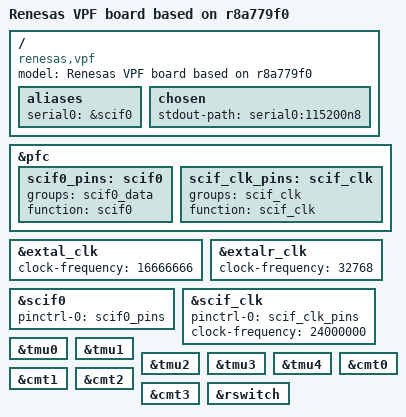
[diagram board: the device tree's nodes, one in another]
// SPDX-License-Identifier: GPL-2.0
/*
 * Device Tree Source for the s4 vpf board
 *
 * Copyright (C) 2020 Renesas Electronics Corp.
 */

/dts-v1/;
#include "r8a779f0.dtsi"

/ {
	model = "Renesas VPF board based on r8a779f0";
	compatible = "renesas,vpf", "renesas,r8a779f0";

	aliases {
		serial0 = &scif0;
	};

	chosen {
		stdout-path = "serial0:115200n8";
	};
};

&pfc {
	scif0_pins: scif0 {
		groups = "scif0_data";
		function = "scif0";
	};

	scif_clk_pins: scif_clk {
		groups = "scif_clk";
		function = "scif_clk";
	};
};

&extal_clk {
	clock-frequency = <16666666>;
};

&extalr_clk {
	clock-frequency = <32768>;
};

&scif0 {
	pinctrl-0 = <&scif0_pins>;
	pinctrl-names = "default";

	status = "okay";
};

&scif_clk {
	pinctrl-0 = <&scif_clk_pins>;
	pinctrl-names = "default";

	clock-frequency = <24000000>;
	status = "okay";
};

&tmu0 {
	status = "okay";
};

&tmu1 {
	status = "okay";
};

&tmu2 {
	status = "okay";
};

&tmu3 {
	status = "okay";
};

&tmu4 {
	status = "okay";
};

&cmt0 {
	status = "okay";
};

&cmt1 {
	status = "okay";
};

&cmt2 {
	status = "okay";
};

&cmt3 {
	status = "okay";
};

&rswitch {
	status = "okay";
};
